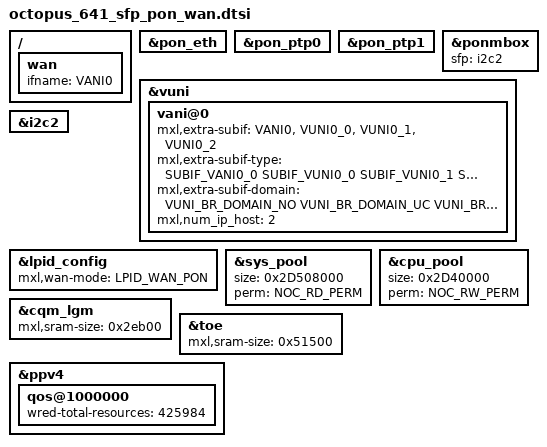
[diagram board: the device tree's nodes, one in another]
// SPDX-License-Identifier: GPL-2.0
/*
 * Copyright (C) 2021-2022 MaxLinear, Inc.
 */

/ {
	wan {
		ifname = "VANI0";
	};
};

&pon_eth {
	status = "okay";
};

&pon_ptp0 {
	status = "okay";
};

&pon_ptp1 {
	status = "okay";
};

&ponmbox {
	status = "okay";
	/* I2C bus to the optical WAN transceiver */
	sfp = <&i2c2>;
};

&vuni {
	status = "okay";
	vani@0 {
		mxl,extra-subif = "VANI0", "VUNI0_0", "VUNI0_1", "VUNI0_2";
		mxl,extra-subif-type = <SUBIF_VANI0_0 SUBIF_VUNI0_0 SUBIF_VUNI0_1 SUBIF_VUNI0_2>;
		mxl,extra-subif-domain = <VUNI_BR_DOMAIN_NO VUNI_BR_DOMAIN_UC VUNI_BR_DOMAIN_MC VUNI_BR_DOMAIN_BC>;
		mxl,num_ip_host = <2>;
	};
};

&i2c2 {
	status = "okay";
};

&lpid_config {
	mxl,wan-mode = <LPID_WAN_PON>;
};

&sys_pool {
	size = <0x2D508000>;
	perm = <NOC_RD_PERM>;
};

&cpu_pool {
	size = <0x2D40000>;
	perm = <NOC_RW_PERM>;
};

&cqm_lgm {
	mxl,sram-size = <0x2eb00>;
};

&toe {
	mxl,sram-size = <0x51500>;
};

&ppv4 {
	qos@1000000 {
		wred-total-resources = <425984>;
	};
};
